# NUC400_v1 register map
File version: 1.0
Registers are 32-bit, read-write, reset 0x0 unless marked. A register's access mark holds for its fields unless they carry their own. Offsets are from the block's base; [hi:lo] are bit positions; {n}, {i} and the like mark numbered series; 'fields as' and 'values as' point back to an identical list.

## RTC — RTC Register Map
Base 0x40041000
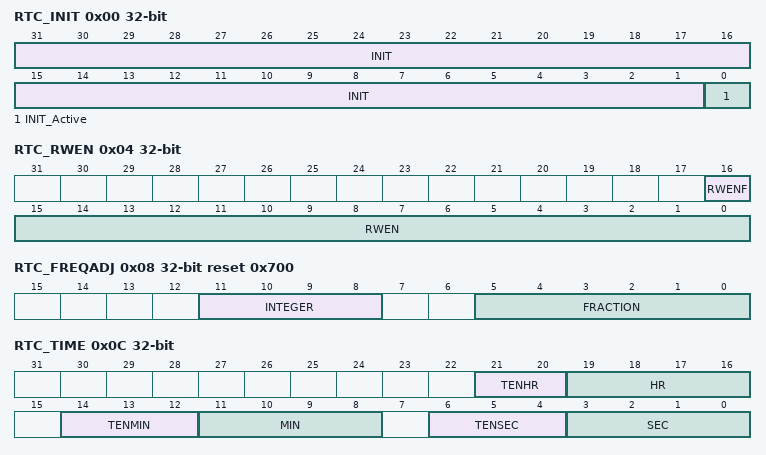
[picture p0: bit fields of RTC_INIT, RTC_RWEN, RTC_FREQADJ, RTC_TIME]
0x00 RTC_INIT — RTC Initiation Register
  [31:1] INIT — RTC Initiation. When RTC block is powered on, RTC is at reset state. User has to write a number (0x a5eb1357) to INIT to make RTC leaving reset state. Once the INIT is written as 0xa5eb1357, the RTC will be in un-reset state permanently. The INIT is a write-only field and read value will be always "0".
  [0] INIT_Active ro — RTC Active Status (Read Only)
    0=RTC is at reset state; 1=RTC is at normal active state
0x04 RTC_RWEN — RTC Access Enable Register
  [16] RWENF ro — RTC Register Access Enable Flag (Read Only)
    0=RTC register read/write Disabled; 1=RTC register read/write Enabled
  [15:0] RWEN wo — RTC Register Access Enable Password (Write Only). Writing 0xA965 to this register will enable RTC access and keep 1024 RTC clock.
0x08 RTC_FREQADJ reset 0x700 — RTC Frequency Compensation Register
  [11:8] INTEGER — Integer Part
  [5:0] FRACTION — Fraction Part. Note: Digit in RTC_FREQADJ must be expressed as hexadecimal number.
0x0C RTC_TIME — Time Loading Register
  [21:20] TENHR — 10-Hour Time Digit (0~2)
  [19:16] HR — 1-Hour Time Digit (0~9)
  [14:12] TENMIN — 10-Min Time Digit (0~5)
  [11:8] MIN — 1-Min Time Digit (0~9)
  [6:4] TENSEC — 10-Sec Time Digit (0~5)
  [3:0] SEC — 1-Sec Time Digit (0~9)
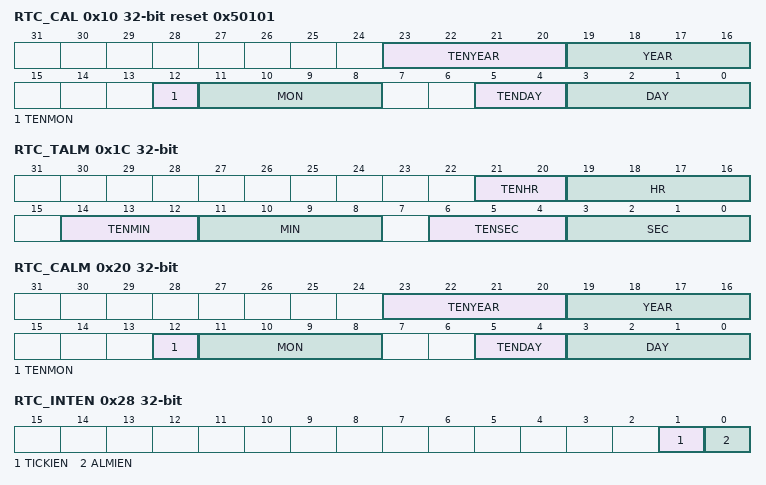
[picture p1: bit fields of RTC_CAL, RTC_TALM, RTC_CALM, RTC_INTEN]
0x10 RTC_CAL reset 0x50101 — Calendar Loading Register
  [23:20] TENYEAR — 10-Year Calendar Digit (0~9)
  [19:16] YEAR — 1-Year Calendar Digit (0~9)
  [12] TENMON — 10-Month Calendar Digit (0~1)
  [11:8] MON — 1-Month Calendar Digit (0~9)
  [5:4] TENDAY — 10-Day Calendar Digit (0~3)
  [3:0] DAY — 1-Day Calendar Digit (0~9)
0x14 RTC_CLKFMT reset 0x1 — Time Scale Selection Register
  [0] _24HEN — 24-Hour / 12-Hour Time Scale Selection
    0=12-hour time scale with AM and PM indication selected; 1=24-hour time scale selected
0x18 RTC_WEEKDAY reset 0x6 — Day of the Week Register
  [2:0] WEEKDAY — Day Of The Week Bits
0x1C RTC_TALM — Time Alarm Register
  [21:20] TENHR — 10-Hour Time Digit of Alarm Setting (0~2)
  [19:16] HR — 1-Hour Time Digit of Alarm Setting (0~9)
  [14:12] TENMIN — 10-Min Time Digit of Alarm Setting (0~5)
  [11:8] MIN — 1-Min Time Digit of Alarm Setting (0~9)
  [6:4] TENSEC — 10-Sec Time Digit of Alarm Setting (0~5)
  [3:0] SEC — 1-Sec Time Digit of Alarm Setting (0~9)
0x20 RTC_CALM — Calendar Alarm Register
  [23:20] TENYEAR — 10-Year Calendar Digit of Alarm Setting (0~9)
  [19:16] YEAR — 1-Year Calendar Digit of Alarm Setting (0~9)
  [12] TENMON — 10-Month Calendar Digit of Alarm Setting (0~1)
  [11:8] MON — 1-Month Calendar Digit of Alarm Setting (0~9)
  [5:4] TENDAY — 10-Day Calendar Digit of Alarm Setting (0~3)
  [3:0] DAY — 1-Day Calendar Digit of Alarm Setting (0~9)
0x24 RTC_LEAPYEAR ro — Leap Year Indication Register
  [0] LEAPYEAR — Leap Year Indicator (Read Only)
    0=This year is not a leap year; 1=This year is leap year
0x28 RTC_INTEN — RTC Interrupt Enable Register
  [1] TICKIEN — Time Tick Interrupt Enable Bit
    0=RTC Time Tick Interrupt Disabled; 1=RTC Time Tick Interrupt Enabled
  [0] ALMIEN — Alarm Interrupt Enable Bit
    0=RTC Alarm Interrupt Disabled; 1=RTC Alarm Interrupt Enabled
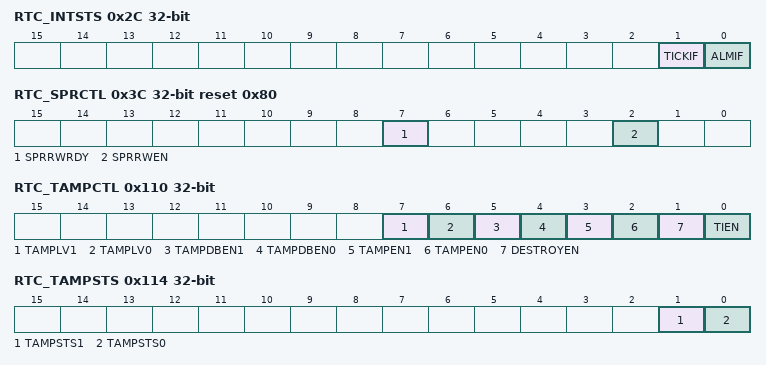
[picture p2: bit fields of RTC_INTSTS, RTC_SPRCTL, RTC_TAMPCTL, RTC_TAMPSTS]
0x2C RTC_INTSTS — RTC Interrupt Indicator Register
  [1] TICKIF — RTC Time Tick Interrupt Flag. When RTC Time Tick happened, this bit will be set to 1 and an interrupt will be generated if RTC Tick Interrupt enabled (TICKIEN (RTC_INTEN[1])) is set to 1. Chip will also be waken up if RTC Tick Interrupt is enabled and this bit is set to 1 when chip is running at Power-down mode. Note: This bit can be cleared by writing 1 to it.
  [0] ALMIF — RTC Alarm Interrupt Flag. When RTC real time counters RTC_TIME and RTC_CAL reach the alarm setting time registers RTC_TALM and RTC_CALM, this bit will be set to 1 and an interrupt will be generated if RTC Alarm Interrupt enabled (ALMIEN (RTC_INTEN(0)) is set to 1. Chip will also be waken up if RTC Alarm Interrupt is enabled and this bit is set to 1 when chip is running at Power-down mode. Note: This bit can be cleared by writing 1 to it.
0x30 RTC_TICK — RTC Time Tick Register
  [2:0] TICKSEL — Time Tick Bits
0x3C RTC_SPRCTL reset 0x80 — RTC Spare Functional Control Register
  [7] SPRRWRDY — SPR Register Ready. This bit indicates if the registers RTC_SPRCTL, RTC_SPR0 ~ RTC_SPR23 are ready to be accessed. After CPU writing registers RTC_SPRCTL, RTC_SPR0 ~ RTC_SPR23, polling this bit to check if these registers are updated done is necessary. This bit is read only and any write to it won't take any effect.
    0=RTC_SPRCTL, RTC_SPR0 ~ RTC_SPR23 updating is in progress; 1=RTC_SPRCTL, RTC_SPR0 ~ RTC_SPR23 are updated done and ready to be accessed
  [2] SPRRWEN — SPR Register Enable Bit. This bit controls the spare register to be enabled or not.
    0=Spare register Disabled and RTC_SPR0 ~ RTC_SPR23 cannot be accessed; 1=Spare register Enabled and RTC_SPR0 ~ RTC_SPR23 can be accessed
{0x40+4i} RTC_SPR{i} (i=0..23) — RTC Spare Register {i}
  [31:0] SPARE — SPARE Bits. This field is used to store back-up information defined by software. This field will be cleared by hardware automatically once a snooper pin event is detected. Before storing back-up information in to SPARE register, software should write 0xA965 to RTC_RWEN to make sure register read/write enabled.
0x110 RTC_TAMPCTL — Tamper Control Register
  [7] TAMPLV1 — Tamper1 Level
    0=Low; 1=High
  [6] TAMPLV0 — Tamper0 Level
    0=Low; 1=High
  [5] TAMPDBEN1 — Tamper1 De-Bounce Enable Bit
    0=Disabled; 1=Enabled
  [4] TAMPDBEN0 — Tamper0 De-Bounce Enable Bit
    0=Disabled; 1=Enabled
  [3] TAMPEN1 — Tamper1 Detect Enable Bit
    0=Disabled; 1=Enabled
  [2] TAMPEN0 — Tamper0 Detect Enable Bit
    0=Disabled; 1=Enabled
  [1] DESTROYEN — Destroy Spare Register Enable Bit
    0=Disabled; 1=Enabled
  [0] TIEN — Tamper Interrupt Enable Bit
    0=Tamper interrupt Disabled; 1=Tamper interrupt Enabled
0x114 RTC_TAMPSTS — Tamper Status Register
  [1] TAMPSTS1 — Tamper1 Sense Flag. Note: Write 1 to clear it
    0=No invasion; 1=Tamper1 detect invasion
  [0] TAMPSTS0 — Tamper0 Sense Flag. Note: Write 1 to clear it
    0=No invasion; 1=Tamper0 detect invasion
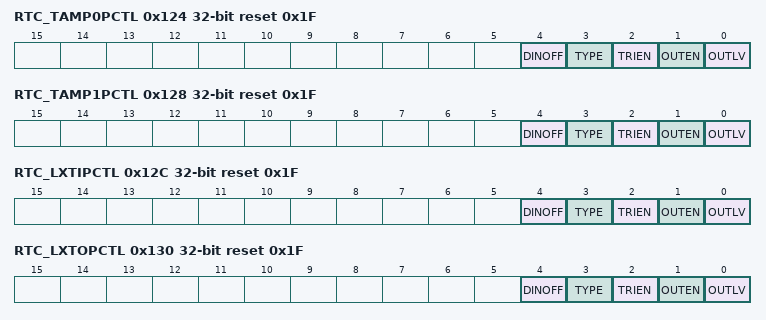
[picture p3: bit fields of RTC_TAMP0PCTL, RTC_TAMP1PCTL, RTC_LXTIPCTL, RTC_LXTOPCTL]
0x124 RTC_TAMP0PCTL reset 0x1F — TAMPER0 Pin I/O Mode Control
  [4] DINOFF — Off Digital
    0=Off digital Disabled; 1=Off digital Enabled
  [3] TYPE
    0=Input Schmitt Trigger function Disabled; 1=Input Schmitt Trigger function Enabled
  [2] TRIEN — Tri-State
    0=Tri-state Disabled; 1=Tri-state Enabled
  [1] OUTEN — Output Enable Bit
    0=Output Enabled; 1=Output Disabled
  [0] OUTLV — Output Level
    0=Low; 1=High
0x128 RTC_TAMP1PCTL reset 0x1F — TAMPER1 Pin I/O Mode Control
  fields as RTC_TAMP0PCTL
0x12C RTC_LXTIPCTL reset 0x1F — 32K Input Pin I/O Mode Control
  fields as RTC_TAMP0PCTL
0x130 RTC_LXTOPCTL reset 0x1F — 32K Output Pin I/O Mode Control
  fields as RTC_TAMP0PCTL
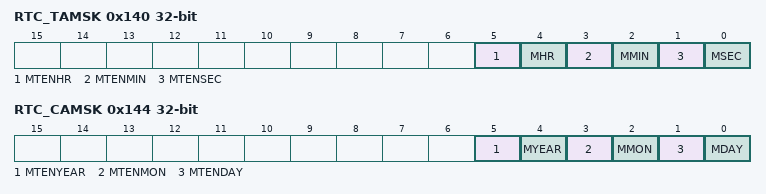
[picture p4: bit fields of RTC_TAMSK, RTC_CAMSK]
0x140 RTC_TAMSK — Time Alarm MASK Register
  [5] MTENHR — Mask 10-Hour Time Digit of Alarm Setting (0~2)
  [4] MHR — Mask 1-Hour Time Digit of Alarm Setting (0~9)
  [3] MTENMIN — Mask 10-Min Time Digit of Alarm Setting (0~5)
  [2] MMIN — Mask 1-Min Time Digit of Alarm Setting (0~9)
  [1] MTENSEC — Mask 10-Sec Time Digit of Alarm Setting (0~5)
  [0] MSEC — Mask 1-Sec Time Digit of Alarm Setting (0~9)
0x144 RTC_CAMSK — Calendar Alarm MASK Register
  [5] MTENYEAR — Mask 10-Year Calendar Digit of Alarm Setting (0~9)
  [4] MYEAR — Mask 1-Year Calendar Digit of Alarm Setting (0~9)
  [3] MTENMON — Mask 10-Month Calendar Digit of Alarm Setting (0~1)
  [2] MMON — Mask 1-Month Calendar Digit of Alarm Setting (0~9)
  [1] MTENDAY — Mask 10-Day Calendar Digit of Alarm Setting (0~3)
  [0] MDAY — Mask 1-Day Calendar Digit of Alarm Setting (0~9)
